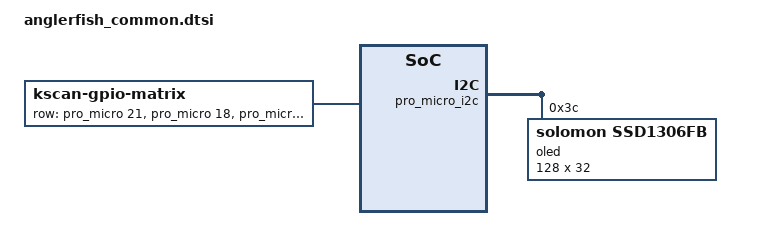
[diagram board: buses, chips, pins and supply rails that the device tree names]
#include <dt-bindings/zmk/matrix_transform.h>

/ {
    chosen {
		zephyr,display = &oled;
		zmk,kscan = &kscan0;
		zmk,matrix_transform = &default_transform;
    };

    kscan0: kscan {
        compatible = "zmk,kscan-gpio-matrix";
        label = "KSCAN";
        diode-direction = "col2row";
		row-gpios
			= <&pro_micro 21 (GPIO_ACTIVE_HIGH | GPIO_PULL_DOWN)>
			, <&pro_micro 18 (GPIO_ACTIVE_HIGH | GPIO_PULL_DOWN)>
			, <&pro_micro 5 (GPIO_ACTIVE_HIGH | GPIO_PULL_DOWN)>
			, <&pro_micro 4 (GPIO_ACTIVE_HIGH | GPIO_PULL_DOWN)>
            ;
    };

    left_encoder: encoder_left {
		compatible = "alps,ec11";
		label = "LEFT_ENCODER";
		resolution = <4>;
		status = "disabled";
	};

	right_encoder: encoder_right {
		compatible = "alps,ec11";
		label = "RIGHT_ENCODER";
		resolution = <4>;
		status = "disabled";
	};

    sensors {
		compatible = "zmk,keymap-sensors";
		sensors = <&left_encoder &right_encoder>;
	};
};

&pro_micro_i2c {
    status = "okay";

    oled: ssd1306@3c {
        compatible = "solomon,ssd1306fb";
        reg = <0x3c>;
        width = <128>;
        height = <32>;
        segment-offset = <0>;
        page-offset = <0>;
        display-offset = <0>;
        multiplex-ratio = <31>;
        segment-remap;
        com-invdir;
        com-sequential;
        inversion-on;
        prechargep = <0x22>;
    };
};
